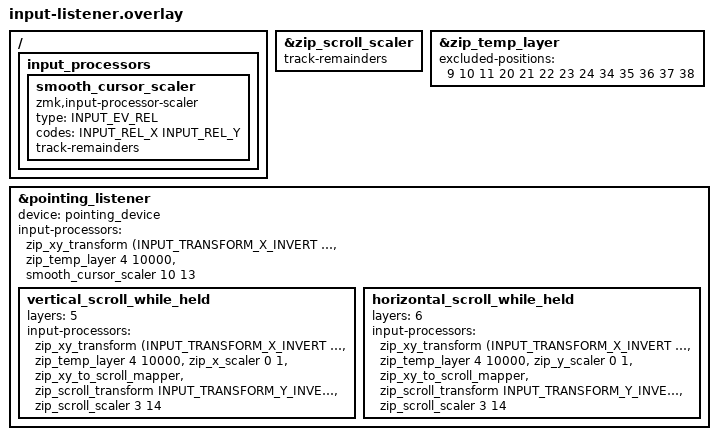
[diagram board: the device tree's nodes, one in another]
// Auto mouse for torabo-tsuki LP: motion activates layer 4 for 10 seconds.
// Keep the stock X/Y inversion for the trackball on either central side.
// Layer 5 is vertical scroll; layer 6 is horizontal scroll.
// M Layout (52 keys) uses physical positions without the L number row.
#include <input/processors.dtsi>
#include <dt-bindings/zmk/input_transform.h>
#include <zephyr/dt-bindings/input/input-event-codes.h>

// Cursor-only scaler: preserve fractional X/Y movement across events.
// Keeps the 10/13 reduction without discarding small individual deltas.
/ {
    input_processors {
        smooth_cursor_scaler: smooth_cursor_scaler {
            compatible = "zmk,input-processor-scaler";
            #input-processor-cells = <2>;
            type = <INPUT_EV_REL>;
            codes = <INPUT_REL_X INPUT_REL_Y>;
            track-remainders;
        };
    };
};

// Preserve fractional wheel movement for both vertical and horizontal scrolling.
// This does not change the 3/14 scroll sensitivity.
&zip_scroll_scaler {
    track-remainders;
};

&zip_temp_layer {
    excluded-positions = <9 10 11 20 21 22 23 24 34 35 36 37 38>;
};

&pointing_listener {
    status = "okay";
    device = <&pointing_device>;

    // The snippet must include the board's original X/Y inversion here,
    // because assigning input-processors replaces the previous list.
    // Pointer movement only: 10/13 (76.92%).
    // Place after zip_temp_layer so auto-mouse activation still sees raw motion.
    input-processors = <&zip_xy_transform (INPUT_TRANSFORM_X_INVERT | INPUT_TRANSFORM_Y_INVERT)>,
                       <&zip_temp_layer 4 10000>,
                       <&smooth_cursor_scaler 10 13>;

    // The scroll overrides replace the default pointer processing.
    // A 0/1 axis scaler suppresses the unwanted axis before conversion.
    // Layer 5: vertical wheel only; horizontal movement is ignored.
    // Scale only wheel events to 21.43%; cursor movement remains unchanged.
    vertical_scroll_while_held {
        layers = <5>;
        input-processors = <&zip_xy_transform (INPUT_TRANSFORM_X_INVERT | INPUT_TRANSFORM_Y_INVERT)>,
                           <&zip_temp_layer 4 10000>,
                           <&zip_x_scaler 0 1>,
                           <&zip_xy_to_scroll_mapper>,
                           <&zip_scroll_transform INPUT_TRANSFORM_Y_INVERT>,
                           <&zip_scroll_scaler 3 14>;
    };

    // Layer 6: horizontal wheel only; vertical movement is ignored.
    // Scale only wheel events to 21.43%; cursor movement remains unchanged.
    horizontal_scroll_while_held {
        layers = <6>;
        input-processors = <&zip_xy_transform (INPUT_TRANSFORM_X_INVERT | INPUT_TRANSFORM_Y_INVERT)>,
                           <&zip_temp_layer 4 10000>,
                           <&zip_y_scaler 0 1>,
                           <&zip_xy_to_scroll_mapper>,
                           <&zip_scroll_transform INPUT_TRANSFORM_Y_INVERT>,
                           <&zip_scroll_scaler 3 14>;
    };
};
